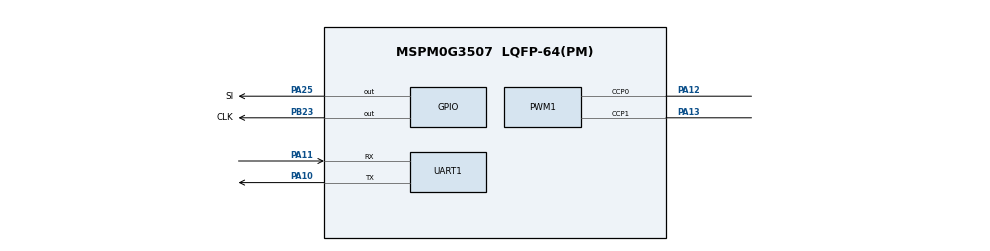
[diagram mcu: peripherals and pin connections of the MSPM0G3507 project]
/**
 * These arguments were used when this file was generated. They will be automatically applied on subsequent loads
 * via the GUI or CLI. Run CLI with '--help' for additional information on how to override these arguments.
 */
//@cliArgs --device "MSPM0G350X" --package "LQFP-64(PM)" --part "Default"
//@v2CliArgs --device "MSPM0G3507" --package "LQFP-64(PM)"
// @cliArgs --board /ti/boards/LP_MSPM0G3507 --rtos nortos

/**
 * Import the modules used in this configuration.
 */
const ADC12  = scripting.addModule("/ti/driverlib/ADC12", {}, false);
const ADC121 = ADC12.addInstance();
const GPIO   = scripting.addModule("/ti/driverlib/GPIO", {}, false);
const GPIO1  = GPIO.addInstance();
const GPIO2  = GPIO.addInstance();
const GPIO3  = GPIO.addInstance();
const PWM    = scripting.addModule("/ti/driverlib/PWM", {}, false);
const PWM1   = PWM.addInstance();
const SYSCTL = scripting.addModule("/ti/driverlib/SYSCTL");
const UART   = scripting.addModule("/ti/driverlib/UART", {}, false);
const UART1  = UART.addInstance();

/**
 * Write custom configuration values to the imported modules.
 */

const Board = scripting.addModule("/ti/driverlib/Board", {}, false);

ADC121.$name                      = "ADC12_0";
ADC121.sampClkDiv                 = "DL_ADC12_CLOCK_DIVIDE_4";
ADC121.sampCnt                    = 1;
ADC121.powerDownMode              = "DL_ADC12_POWER_DOWN_MODE_MANUAL";
ADC121.sampleTime0                = "1us";
ADC121.peripheral.$assign         = "ADC0";
ADC121.peripheral.adcPin0.$assign = "PA27";
ADC121.adcPin0Config.$name        = "ti_driverlib_gpio_GPIOPinGeneric5";

SYSCTL.forceDefaultClkConfig = true;

GPIO1.$name                         = "GPIO_LEDS";
GPIO1.port                          = "PORTB";
GPIO1.associatedPins.create(1);
GPIO1.associatedPins[0].$name       = "USER_LED_1";
GPIO1.associatedPins[0].assignedPin = "22";

GPIO2.$name                               = "GPIO_DC";
GPIO2.port                                = "PORTB";
GPIO2.associatedPins.create(2);
GPIO2.associatedPins[0].$name             = "AIN0";
GPIO2.associatedPins[0].direction         = "OUTPUT";
GPIO2.associatedPins[0].initialValue      = "CLEARED";
GPIO2.associatedPins[0].assignedPort      = "PORTB";
GPIO2.associatedPins[0].assignedPin       = "8";
GPIO2.associatedPins[1].$name             = "AIN2";
GPIO2.associatedPins[1].direction         = "OUTPUT";
GPIO2.associatedPins[1].initialValue      = "CLEARED";
GPIO2.associatedPins[1].assignedPort      = "PORTB";
GPIO2.associatedPins[1].assignedPin       = "6";

GPIO3.$name                         = "GPIO_CCD";
GPIO3.associatedPins.create(2);
GPIO3.associatedPins[0].$name       = "SI";
GPIO3.associatedPins[0].direction   = "OUTPUT";
GPIO3.associatedPins[0].pin.$assign = "PA25";
GPIO3.associatedPins[1].$name       = "CLK";
GPIO3.associatedPins[1].direction   = "OUTPUT";
GPIO3.associatedPins[1].pin.$assign = "PB23";

PWM1.$name                              = "PWM_DC";
PWM1.timerCount                         = 10000;
PWM1.clockDivider                       = 4;
PWM1.clockPrescale                      = 8;
PWM1.peripheral.$assign                 = "TIMG0";
PWM1.peripheral.ccp0Pin.$assign         = "PA12";
PWM1.peripheral.ccp1Pin.$assign         = "PA13";
PWM1.PWM_CHANNEL_0.$name                = "ti_driverlib_pwm_PWMTimerCC0";
PWM1.PWM_CHANNEL_0.dutyCycle            = 2;
PWM1.PWM_CHANNEL_1.$name                = "ti_driverlib_pwm_PWMTimerCC1";
PWM1.PWM_CHANNEL_1.dutyCycle            = 2;
PWM1.ccp0PinConfig.direction            = scripting.forceWrite("OUTPUT");
PWM1.ccp0PinConfig.hideOutputInversion  = scripting.forceWrite(false);
PWM1.ccp0PinConfig.onlyInternalResistor = scripting.forceWrite(false);
PWM1.ccp0PinConfig.passedPeripheralType = scripting.forceWrite("Digital");
PWM1.ccp0PinConfig.$name                = "ti_driverlib_gpio_GPIOPinGeneric3";
PWM1.ccp1PinConfig.direction            = scripting.forceWrite("OUTPUT");
PWM1.ccp1PinConfig.hideOutputInversion  = scripting.forceWrite(false);
PWM1.ccp1PinConfig.onlyInternalResistor = scripting.forceWrite(false);
PWM1.ccp1PinConfig.passedPeripheralType = scripting.forceWrite("Digital");
PWM1.ccp1PinConfig.$name                = "ti_driverlib_gpio_GPIOPinGeneric4";

UART1.targetBaudRate                   = 115200;
UART1.$name                            = "UART_K230";
UART1.enabledInterrupts                = [];
UART1.peripheral.$assign               = "UART0";
UART1.peripheral.rxPin.$assign         = "PA11";
UART1.peripheral.txPin.$assign         = "PA10";
UART1.txPinConfig.direction            = scripting.forceWrite("OUTPUT");
UART1.txPinConfig.hideOutputInversion  = scripting.forceWrite(false);
UART1.txPinConfig.onlyInternalResistor = scripting.forceWrite(false);
UART1.txPinConfig.passedPeripheralType = scripting.forceWrite("Digital");
UART1.txPinConfig.$name                = "ti_driverlib_gpio_GPIOPinGeneric1";
UART1.rxPinConfig.hideOutputInversion  = scripting.forceWrite(false);
UART1.rxPinConfig.onlyInternalResistor = scripting.forceWrite(false);
UART1.rxPinConfig.passedPeripheralType = scripting.forceWrite("Digital");
UART1.rxPinConfig.$name                = "ti_driverlib_gpio_GPIOPinGeneric2";
